AUTOSAR XML (schema 3.1.2)
package /Components/SWC_TrbActGsl
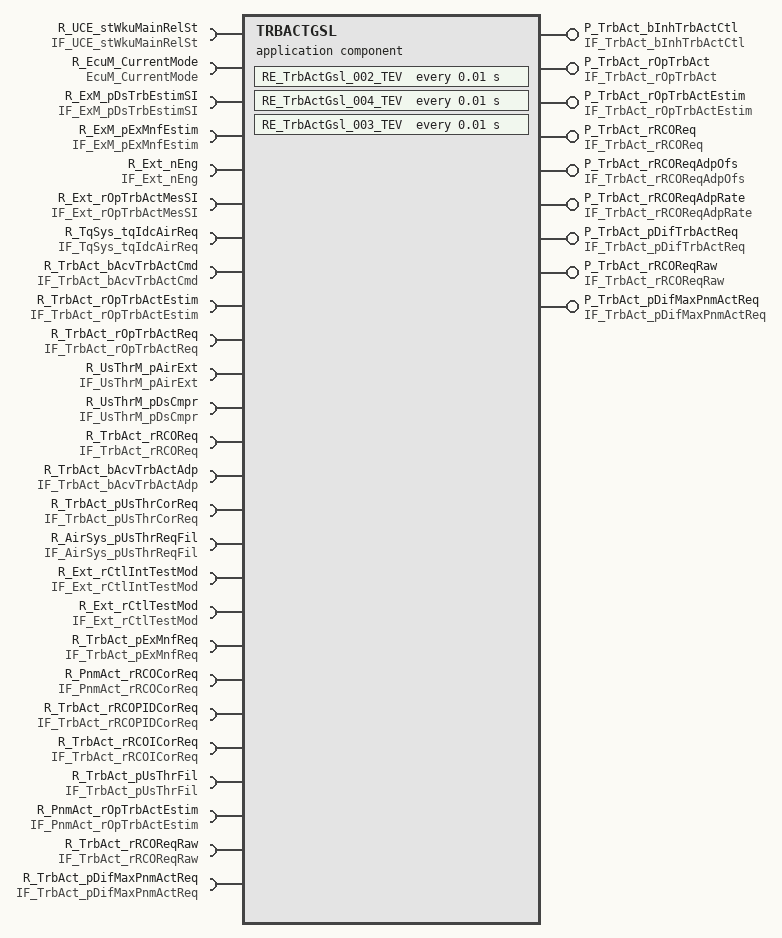
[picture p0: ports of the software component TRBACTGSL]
  application software component type TRBACTGSL  # TrbActGsl
    require port R_UCE_stWkuMainRelSt: required-interface=IF_UCE_stWkuMainRelSt
    9 x provide port:
      P_TrbAct_bInhTrbActCtl: unqueued-sender-com-spec{data-element=TrbAct_bInhTrbActCtl, can-invalidate=false, init-value=BooleanInitValue}, provided-interface=IF_TrbAct_bInhTrbActCtl
      P_TrbAct_rOpTrbAct: unqueued-sender-com-spec{data-element=TrbAct_rOpTrbAct, can-invalidate=false, init-value=UInt16InitValue}, provided-interface=IF_TrbAct_rOpTrbAct
      P_TrbAct_rOpTrbActEstim: unqueued-sender-com-spec{data-element=TrbAct_rOpTrbActEstim, can-invalidate=false, init-value=UInt16InitValue1}, provided-interface=IF_TrbAct_rOpTrbActEstim
      P_TrbAct_rRCOReq: unqueued-sender-com-spec{data-element=TrbAct_rRCOReq, can-invalidate=false, init-value=UInt16InitValue3}, provided-interface=IF_TrbAct_rRCOReq
      P_TrbAct_rRCOReqAdpOfs: unqueued-sender-com-spec{data-element=TrbAct_rRCOReqAdpOfs, can-invalidate=false, init-value=SInt16InitValue}, provided-interface=IF_TrbAct_rRCOReqAdpOfs
      P_TrbAct_rRCOReqAdpRate: unqueued-sender-com-spec{data-element=TrbAct_rRCOReqAdpRate, can-invalidate=false, init-value=UInt16InitValue5}, provided-interface=IF_TrbAct_rRCOReqAdpRate
      P_TrbAct_pDifTrbActReq: unqueued-sender-com-spec{data-element=TrbAct_pDifTrbActReq, can-invalidate=false, init-value=ConstantValue}, provided-interface=IF_TrbAct_pDifTrbActReq
      P_TrbAct_rRCOReqRaw: unqueued-sender-com-spec{data-element=TrbAct_rRCOReqRaw, can-invalidate=false, init-value=ConstantValue7}, provided-interface=IF_TrbAct_rRCOReqRaw
      P_TrbAct_pDifMaxPnmActReq: unqueued-sender-com-spec{data-element=TrbAct_pDifMaxPnmActReq, can-invalidate=false, init-value=ConstantValue9}, provided-interface=IF_TrbAct_pDifMaxPnmActReq
    25 x require port:
      R_EcuM_CurrentMode: required-interface=EcuM_CurrentMode
      R_ExM_pDsTrbEstimSI: unqueued-receiver-com-spec{data-element=ExM_pDsTrbEstimSI, init-value=ConstantValue11, resync-time=0}, required-interface=IF_ExM_pDsTrbEstimSI
      R_ExM_pExMnfEstim: unqueued-receiver-com-spec{data-element=ExM_pExMnfEstim, init-value=ConstantValue13, resync-time=0}, required-interface=IF_ExM_pExMnfEstim
      R_Ext_nEng: unqueued-receiver-com-spec{data-element=Ext_nEng, init-value=ConstantValue15, resync-time=0}, required-interface=IF_Ext_nEng
      R_Ext_rOpTrbActMesSI: unqueued-receiver-com-spec{data-element=Ext_rOpTrbActMesSI, init-value=UInt16InitValue17, resync-time=0}, required-interface=IF_Ext_rOpTrbActMesSI
      R_TqSys_tqIdcAirReq: unqueued-receiver-com-spec{data-element=TqSys_tqIdcAirReq, init-value=SInt16InitValue19, resync-time=0}, required-interface=IF_TqSys_tqIdcAirReq
      R_TrbAct_bAcvTrbActCmd: unqueued-receiver-com-spec{data-element=TrbAct_bAcvTrbActCmd, init-value=BooleanInitValue21, resync-time=0}, required-interface=IF_TrbAct_bAcvTrbActCmd
      R_TrbAct_rOpTrbActEstim: unqueued-receiver-com-spec{data-element=TrbAct_rOpTrbActEstim, init-value=UInt16InitValue23, resync-time=0}, required-interface=IF_TrbAct_rOpTrbActEstim
      R_TrbAct_rOpTrbActReq: unqueued-receiver-com-spec{data-element=TrbAct_rOpTrbActReq, init-value=UInt16InitValue25, resync-time=0}, required-interface=IF_TrbAct_rOpTrbActReq
      R_UsThrM_pAirExt: unqueued-receiver-com-spec{data-element=UsThrM_pAirExt, init-value=ConstantValue27, resync-time=0}, required-interface=IF_UsThrM_pAirExt
      R_UsThrM_pDsCmpr: unqueued-receiver-com-spec{data-element=UsThrM_pDsCmpr, init-value=ConstantValue29, resync-time=0}, required-interface=IF_UsThrM_pDsCmpr
      R_TrbAct_rRCOReq: unqueued-receiver-com-spec{data-element=TrbAct_rRCOReq, init-value=UInt16InitValue31, resync-time=0}, required-interface=IF_TrbAct_rRCOReq
      R_TrbAct_bAcvTrbActAdp: unqueued-receiver-com-spec{data-element=TrbAct_bAcvTrbActAdp, init-value=BooleanInitValue33, resync-time=0}, required-interface=IF_TrbAct_bAcvTrbActAdp
      R_TrbAct_pUsThrCorReq: unqueued-receiver-com-spec{data-element=TrbAct_pUsThrCorReq, init-value=UInt16InitValue35, resync-time=0}, required-interface=IF_TrbAct_pUsThrCorReq
      R_AirSys_pUsThrReqFil: unqueued-receiver-com-spec{data-element=AirSys_pUsThrReqFil, init-value=ConstantValue37, resync-time=0}, required-interface=IF_AirSys_pUsThrReqFil
      R_Ext_rCtlIntTestMod: unqueued-receiver-com-spec{data-element=Ext_rCtlIntTestMod, init-value=SInt16InitValue39, resync-time=0}, required-interface=IF_Ext_rCtlIntTestMod
      R_Ext_rCtlTestMod: unqueued-receiver-com-spec{data-element=Ext_rCtlTestMod, init-value=SInt16InitValue41, resync-time=0}, required-interface=IF_Ext_rCtlTestMod
      R_TrbAct_pExMnfReq: unqueued-receiver-com-spec{data-element=TrbAct_pExMnfReq, init-value=UInt16InitValue43, resync-time=0}, required-interface=IF_TrbAct_pExMnfReq
      R_PnmAct_rRCOCorReq: unqueued-receiver-com-spec{data-element=PnmAct_rRCOCorReq, init-value=ConstantValue45, resync-time=0}, required-interface=IF_PnmAct_rRCOCorReq
      R_TrbAct_rRCOPIDCorReq: unqueued-receiver-com-spec{data-element=TrbAct_rRCOPIDCorReq, init-value=SInt16InitValue47, resync-time=0}, required-interface=IF_TrbAct_rRCOPIDCorReq
      R_TrbAct_rRCOICorReq: unqueued-receiver-com-spec{data-element=TrbAct_rRCOICorReq, init-value=SInt16InitValue49, resync-time=0}, required-interface=IF_TrbAct_rRCOICorReq
      R_TrbAct_pUsThrFil: unqueued-receiver-com-spec{data-element=TrbAct_pUsThrFil, init-value=UInt16InitValue51, resync-time=0}, required-interface=IF_TrbAct_pUsThrFil
      R_PnmAct_rOpTrbActEstim: unqueued-receiver-com-spec{data-element=PnmAct_rOpTrbActEstim, init-value=ConstantValue53, resync-time=0}, required-interface=IF_PnmAct_rOpTrbActEstim
      R_TrbAct_rRCOReqRaw: unqueued-receiver-com-spec{data-element=TrbAct_rRCOReqRaw, init-value=ConstantValue55, resync-time=0}, required-interface=IF_TrbAct_rRCOReqRaw
      R_TrbAct_pDifMaxPnmActReq: unqueued-receiver-com-spec{data-element=TrbAct_pDifMaxPnmActReq, init-value=ConstantValue57, resync-time=0}, required-interface=IF_TrbAct_pDifMaxPnmActReq
  34 x constant specification:
    BooleanInitValue
      value:
        boolean literal BooleanInitValue: type=DT_TrbAct_bInhTrbActCtl, value=true
    BooleanInitValue21
      value:
        boolean literal BooleanInitValue21: type=DT_TrbAct_bAcvTrbActCmd, value=false
    BooleanInitValue33
      value:
        boolean literal BooleanInitValue33: type=DT_TrbAct_bAcvTrbActAdp, value=false
    ConstantValue
      value:
        integer literal ConstantValue: type=DT_TrbAct_pDifTrbActReq, value=0
    ConstantValue11
      value:
        integer literal ConstantValue11: type=DT_ExM_pDsTrbEstimSI, value=0
    ConstantValue13
      value:
        integer literal ConstantValue13: type=DT_ExM_pExMnfEstim, value=0
    ConstantValue15
      value:
        integer literal ConstantValue15: type=DT_Ext_nEng, value=0
    ConstantValue27
      value:
        integer literal ConstantValue27: type=DT_UsThrM_pAirExt, value=0
    ConstantValue29
      value:
        integer literal ConstantValue29: type=DT_UsThrM_pDsCmpr, value=0
    ConstantValue37
      value:
        integer literal ConstantValue37: type=DT_AirSys_pUsThrReqFil, value=0
    ConstantValue45
      value:
        integer literal ConstantValue45: type=DT_PnmAct_rRCOCorReq, value=-32767
    ConstantValue53
      value:
        integer literal ConstantValue53: type=DT_PnmAct_rOpTrbActEstim, value=0
    ConstantValue55
      value:
        integer literal ConstantValue55: type=DT_TrbAct_rRCOReqRaw, value=0
    ConstantValue57
      value:
        integer literal ConstantValue57: type=DT_TrbAct_pDifMaxPnmActReq, value=0
    ConstantValue7
      value:
        integer literal ConstantValue7: type=DT_TrbAct_rRCOReqRaw, value=0
    ConstantValue9
      value:
        integer literal ConstantValue9: type=DT_TrbAct_pDifMaxPnmActReq, value=0
    InitValue_SInt16_0
      value:
        integer literal InitValue_SInt16_0: type=DT_TrbAct_pDifTrbEstim_irv, value=0
    SInt16InitValue
      value:
        integer literal SInt16InitValue: type=DT_TrbAct_rRCOReqAdpOfs, value=0
    SInt16InitValue19
      value:
        integer literal SInt16InitValue19: type=DT_TqSys_tqIdcAirReq, value=-32000
    SInt16InitValue39
      value:
        integer literal SInt16InitValue39: type=DT_Ext_rCtlIntTestMod, value=-32767
    SInt16InitValue41
      value:
        integer literal SInt16InitValue41: type=DT_Ext_rCtlTestMod, value=-32767
    SInt16InitValue47
      value:
        integer literal SInt16InitValue47: type=DT_TrbAct_rRCOPIDCorReq, value=0
    SInt16InitValue49
      value:
        integer literal SInt16InitValue49: type=DT_TrbAct_rRCOICorReq, value=0
    UInt16InitValue
      value:
        integer literal UInt16InitValue: type=DT_TrbAct_rOpTrbAct, value=0
    UInt16InitValue1
      value:
        integer literal UInt16InitValue1: type=DT_TrbAct_rOpTrbActEstim, value=0
    UInt16InitValue17
      value:
        integer literal UInt16InitValue17: type=DT_Ext_rOpTrbActMesSI, value=0
    UInt16InitValue23
      value:
        integer literal UInt16InitValue23: type=DT_TrbAct_rOpTrbActEstim, value=0
    UInt16InitValue25
      value:
        integer literal UInt16InitValue25: type=DT_TrbAct_rOpTrbActReq, value=0
    UInt16InitValue3
      value:
        integer literal UInt16InitValue3: type=DT_TrbAct_rRCOReq, value=0
    UInt16InitValue31
      value:
        integer literal UInt16InitValue31: type=DT_TrbAct_rRCOReq, value=0
    UInt16InitValue35
      value:
        integer literal UInt16InitValue35: type=DT_TrbAct_pUsThrCorReq, value=0
    UInt16InitValue43
      value:
        integer literal UInt16InitValue43: type=DT_TrbAct_pExMnfReq, value=0
    UInt16InitValue5
      value:
        integer literal UInt16InitValue5: type=DT_TrbAct_rRCOReqAdpRate, value=32768
    UInt16InitValue51
      value:
        integer literal UInt16InitValue51: type=DT_TrbAct_pUsThrFil, value=0
  internal behavior IB_TrbActGsl: component=TRBACTGSL
    timing event EV_TrbActGsl_002_TEV: start-on-event=RE_TrbActGsl_002_TEV, period=0.01
    timing event EV_TrbActGsl_004_TEV: start-on-event=RE_TrbActGsl_004_TEV, period=0.01
    timing event EV_TrbActGsl_003_TEV: start-on-event=RE_TrbActGsl_003_TEV, period=0.01
    mode switch event EV_TrbActGsl_001_MSE: start-on-event=RE_TrbActGsl_001_MSE, activation=ENTRY, mode=R_EcuM_CurrentMode.currentMode.RUN
    inter runnable variable TrbAct_pDifTrbEstim_irv: sw-calibration-access=READ-WRITE, type=DT_TrbAct_pDifTrbEstim_irv, communication-approach=EXPLICIT, init-value=InitValue_SInt16_0
    4 x runnable:
      RE_TrbActGsl_004_TEV: read-variable=TrbAct_pDifTrbEstim_irv
        5 x data receive point:
          dr_PnmAct_rOpTrbActEstim: data-element=R_PnmAct_rOpTrbActEstim.PnmAct_rOpTrbActEstim
          dr_TrbAct_pDifMaxPnmActReq: data-element=R_TrbAct_pDifMaxPnmActReq.TrbAct_pDifMaxPnmActReq
          dr_Ext_rOpTrbActMesSI: data-element=R_Ext_rOpTrbActMesSI.Ext_rOpTrbActMesSI
          dr_TrbAct_rOpTrbActEstim: data-element=R_TrbAct_rOpTrbActEstim.TrbAct_rOpTrbActEstim
          dr_TrbAct_rRCOReq: data-element=R_TrbAct_rRCOReq.TrbAct_rRCOReq
        data send point ds_TrbAct_rOpTrbActEstim: data-element=P_TrbAct_rOpTrbActEstim.TrbAct_rOpTrbActEstim
        data send point ds_TrbAct_rOpTrbAct: data-element=P_TrbAct_rOpTrbAct.TrbAct_rOpTrbAct
      RE_TrbActGsl_001_MSE: written-variable=TrbAct_pDifTrbEstim_irv
        9 x data send point:
          ds_TrbAct_bInhTrbActCtl: data-element=P_TrbAct_bInhTrbActCtl.TrbAct_bInhTrbActCtl
          ds_TrbAct_rRCOReqRaw: data-element=P_TrbAct_rRCOReqRaw.TrbAct_rRCOReqRaw
          ds_TrbAct_rOpTrbActEstim: data-element=P_TrbAct_rOpTrbActEstim.TrbAct_rOpTrbActEstim
          ds_TrbAct_pDifTrbActReq: data-element=P_TrbAct_pDifTrbActReq.TrbAct_pDifTrbActReq
          ds_TrbAct_rRCOReq: data-element=P_TrbAct_rRCOReq.TrbAct_rRCOReq
          ds_TrbAct_rRCOReqAdpOfs: data-element=P_TrbAct_rRCOReqAdpOfs.TrbAct_rRCOReqAdpOfs
          ds_TrbAct_pDifMaxPnmActReq: data-element=P_TrbAct_pDifMaxPnmActReq.TrbAct_pDifMaxPnmActReq
          ds_TrbAct_rRCOReqAdpRate: data-element=P_TrbAct_rRCOReqAdpRate.TrbAct_rRCOReqAdpRate
          ds_TrbAct_rOpTrbAct: data-element=P_TrbAct_rOpTrbAct.TrbAct_rOpTrbAct
      RE_TrbActGsl_002_TEV: written-variable=TrbAct_pDifTrbEstim_irv
        7 x data receive point:
          dr_TrbAct_rOpTrbActReq: data-element=R_TrbAct_rOpTrbActReq.TrbAct_rOpTrbActReq
          dr_ExM_pExMnfEstim: data-element=R_ExM_pExMnfEstim.ExM_pExMnfEstim
          dr_UsThrM_pDsCmpr: data-element=R_UsThrM_pDsCmpr.UsThrM_pDsCmpr
          dr_ExM_pDsTrbEstimSI: data-element=R_ExM_pDsTrbEstimSI.ExM_pDsTrbEstimSI
          dr_UsThrM_pAirExt: data-element=R_UsThrM_pAirExt.UsThrM_pAirExt
          dr_Ext_nEng: data-element=R_Ext_nEng.Ext_nEng
          dr_TrbAct_pExMnfReq: data-element=R_TrbAct_pExMnfReq.TrbAct_pExMnfReq
        4 x data send point:
          ds_TrbAct_pDifMaxPnmActReq: data-element=P_TrbAct_pDifMaxPnmActReq.TrbAct_pDifMaxPnmActReq
          ds_TrbAct_bInhTrbActCtl: data-element=P_TrbAct_bInhTrbActCtl.TrbAct_bInhTrbActCtl
          ds_TrbAct_pDifTrbActReq: data-element=P_TrbAct_pDifTrbActReq.TrbAct_pDifTrbActReq
          ds_TrbAct_rRCOReqRaw: data-element=P_TrbAct_rRCOReqRaw.TrbAct_rRCOReqRaw
      RE_TrbActGsl_003_TEV
        14 x data receive point:
          dr_AirSys_pUsThrReqFil: data-element=R_AirSys_pUsThrReqFil.AirSys_pUsThrReqFil
          dr_PnmAct_rRCOCorReq: data-element=R_PnmAct_rRCOCorReq.PnmAct_rRCOCorReq
          dr_TrbAct_rRCOPIDCorReq: data-element=R_TrbAct_rRCOPIDCorReq.TrbAct_rRCOPIDCorReq
          dr_TrbAct_rRCOReqRaw: data-element=R_TrbAct_rRCOReqRaw.TrbAct_rRCOReqRaw
          dr_Ext_rCtlIntTestMod: data-element=R_Ext_rCtlIntTestMod.Ext_rCtlIntTestMod
          dr_Ext_rCtlTestMod: data-element=R_Ext_rCtlTestMod.Ext_rCtlTestMod
          dr_Ext_nEng: data-element=R_Ext_nEng.Ext_nEng
          dr_TrbAct_pUsThrFil: data-element=R_TrbAct_pUsThrFil.TrbAct_pUsThrFil
          dr_TrbAct_rOpTrbActReq: data-element=R_TrbAct_rOpTrbActReq.TrbAct_rOpTrbActReq
          dr_TrbAct_rRCOICorReq: data-element=R_TrbAct_rRCOICorReq.TrbAct_rRCOICorReq
          dr_TrbAct_bAcvTrbActAdp: data-element=R_TrbAct_bAcvTrbActAdp.TrbAct_bAcvTrbActAdp
          dr_TrbAct_bAcvTrbActCmd: data-element=R_TrbAct_bAcvTrbActCmd.TrbAct_bAcvTrbActCmd
          dr_TqSys_tqIdcAirReq: data-element=R_TqSys_tqIdcAirReq.TqSys_tqIdcAirReq
          dr_TrbAct_pUsThrCorReq: data-element=R_TrbAct_pUsThrCorReq.TrbAct_pUsThrCorReq
        data send point ds_TrbAct_rRCOReq: data-element=P_TrbAct_rRCOReq.TrbAct_rRCOReq
        data send point ds_TrbAct_rRCOReqAdpOfs: data-element=P_TrbAct_rRCOReqAdpOfs.TrbAct_rRCOReqAdpOfs
        data send point ds_TrbAct_rRCOReqAdpRate: data-element=P_TrbAct_rRCOReqAdpRate.TrbAct_rRCOReqAdpRate
  swc implementation Imp_TrbActGsl: code-generator=Real-Time Workshop Embedded Coder 5.5 (R2010a) 25-Jan-2010, programming-language=C, behavior=IB_TrbActGsl
    code-descriptors:
      code CodeDescriptor: type=SRC
        12 x xfile:
          TrbActGsl_Version_h: url=TrbActGsl_Version.h
          TrbActGsl_MemMap_h: url=TrbActGsl_MemMap.h
          TrbActGsl_data_c: url=TrbActGsl_data.c
          TrbActGsl_nvm_c: url=TrbActGsl_nvm.c
          TrbActGsl_Def_c: url=TrbActGsl_Def.c
          TrbActGsl_c: url=TrbActGsl.c
          TrbActGsl_h: url=TrbActGsl.h
          TrbActGsl_types_h: url=TrbActGsl_types.h
          TrbActGsl_nvm_h: url=TrbActGsl_nvm.h
          TrbActGsl_Version_c: url=TrbActGsl_Version.c
          TrbActGsl_import_h: url=TrbActGsl_import.h
          TrbActGsl_private_h: url=TrbActGsl_private.h
package /Components/SWC_TrbActGsl/TrbActGsl_IRVDatatypes
  integer type DT_TrbAct_pDifTrbEstim_irv: base-type=int16, lower-limit=-32768, upper-limit=32767
